# cpsw_9xuss_j7am0_CPSW_NUSS_VBUSP register map
Vendor: Texas Instruments
Registers are 32-bit, read-write, reset 0x0 unless marked. A register's access mark holds for its fields unless they carry their own. Offsets are as the file gives them; [hi:lo] are bit positions; {n}, {i} and the like mark numbered series; 'fields as' and 'values as' point back to an identical list.

## cpsw_9xuss_j7am0_CPSW_NUSS_VBUSP (part 3 of 3)
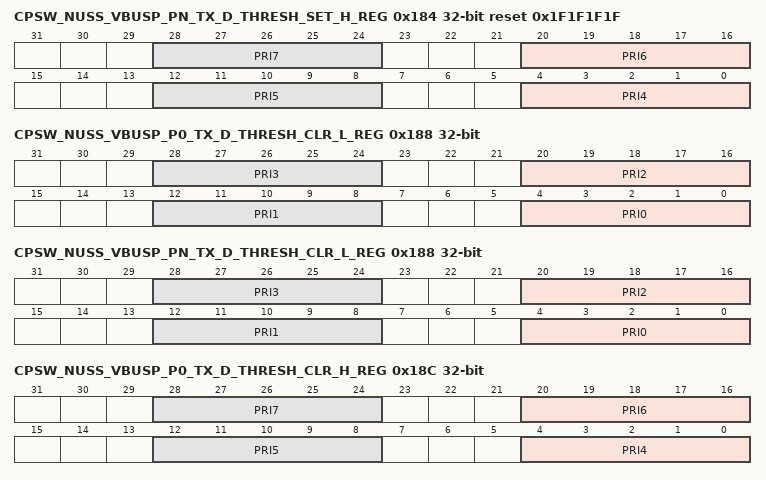
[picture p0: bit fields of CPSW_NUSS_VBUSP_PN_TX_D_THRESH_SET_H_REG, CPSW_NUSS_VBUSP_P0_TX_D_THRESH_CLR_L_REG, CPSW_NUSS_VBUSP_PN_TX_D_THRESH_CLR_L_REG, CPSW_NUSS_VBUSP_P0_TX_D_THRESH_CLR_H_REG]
0x184 CPSW_NUSS_VBUSP_PN_TX_D_THRESH_SET_H_REG reset 0x1F1F1F1F
  [8n-28:8n-32] PRI{n} (n=4..7) — Port Priority Based Flow Control Threshold Set Value for Priority {n}
0x184 CPSW_NUSS_VBUSP_PN_TX_D_THRESH_SET_H_REG reset 0x1F1F1F1F
  fields as CPSW_NUSS_VBUSP_PN_TX_D_THRESH_SET_H_REG
0x184 CPSW_NUSS_VBUSP_PN_TX_D_THRESH_SET_H_REG reset 0x1F1F1F1F
  fields as CPSW_NUSS_VBUSP_PN_TX_D_THRESH_SET_H_REG
0x184 CPSW_NUSS_VBUSP_PN_TX_D_THRESH_SET_H_REG reset 0x1F1F1F1F
  fields as CPSW_NUSS_VBUSP_PN_TX_D_THRESH_SET_H_REG
0x184 CPSW_NUSS_VBUSP_PN_TX_D_THRESH_SET_H_REG reset 0x1F1F1F1F
  fields as CPSW_NUSS_VBUSP_PN_TX_D_THRESH_SET_H_REG
0x184 CPSW_NUSS_VBUSP_PN_TX_D_THRESH_SET_H_REG reset 0x1F1F1F1F
  fields as CPSW_NUSS_VBUSP_PN_TX_D_THRESH_SET_H_REG
0x184 CPSW_NUSS_VBUSP_PN_TX_D_THRESH_SET_H_REG reset 0x1F1F1F1F
  fields as CPSW_NUSS_VBUSP_PN_TX_D_THRESH_SET_H_REG
0x184 CPSW_NUSS_VBUSP_PN_TX_D_THRESH_SET_H_REG reset 0x1F1F1F1F
  fields as CPSW_NUSS_VBUSP_PN_TX_D_THRESH_SET_H_REG
0x188 CPSW_NUSS_VBUSP_P0_TX_D_THRESH_CLR_L_REG
  [8n+4:8n] PRI{n} (n=0..3) — Port Priority Based Flow Control Threshold Clear Value for Priority {n}
0x188 CPSW_NUSS_VBUSP_PN_TX_D_THRESH_CLR_L_REG
  fields as CPSW_NUSS_VBUSP_P0_TX_D_THRESH_CLR_L_REG
0x188 CPSW_NUSS_VBUSP_PN_TX_D_THRESH_CLR_L_REG
  fields as CPSW_NUSS_VBUSP_P0_TX_D_THRESH_CLR_L_REG
0x188 CPSW_NUSS_VBUSP_PN_TX_D_THRESH_CLR_L_REG
  fields as CPSW_NUSS_VBUSP_P0_TX_D_THRESH_CLR_L_REG
0x188 CPSW_NUSS_VBUSP_PN_TX_D_THRESH_CLR_L_REG
  fields as CPSW_NUSS_VBUSP_P0_TX_D_THRESH_CLR_L_REG
0x188 CPSW_NUSS_VBUSP_PN_TX_D_THRESH_CLR_L_REG
  fields as CPSW_NUSS_VBUSP_P0_TX_D_THRESH_CLR_L_REG
0x188 CPSW_NUSS_VBUSP_PN_TX_D_THRESH_CLR_L_REG
  fields as CPSW_NUSS_VBUSP_P0_TX_D_THRESH_CLR_L_REG
0x188 CPSW_NUSS_VBUSP_PN_TX_D_THRESH_CLR_L_REG
  fields as CPSW_NUSS_VBUSP_P0_TX_D_THRESH_CLR_L_REG
0x188 CPSW_NUSS_VBUSP_PN_TX_D_THRESH_CLR_L_REG
  fields as CPSW_NUSS_VBUSP_P0_TX_D_THRESH_CLR_L_REG
0x18C CPSW_NUSS_VBUSP_P0_TX_D_THRESH_CLR_H_REG
  [8n-28:8n-32] PRI{n} (n=4..7) — Port Priority Based Flow Control Threshold Clear Value for Priority {n}
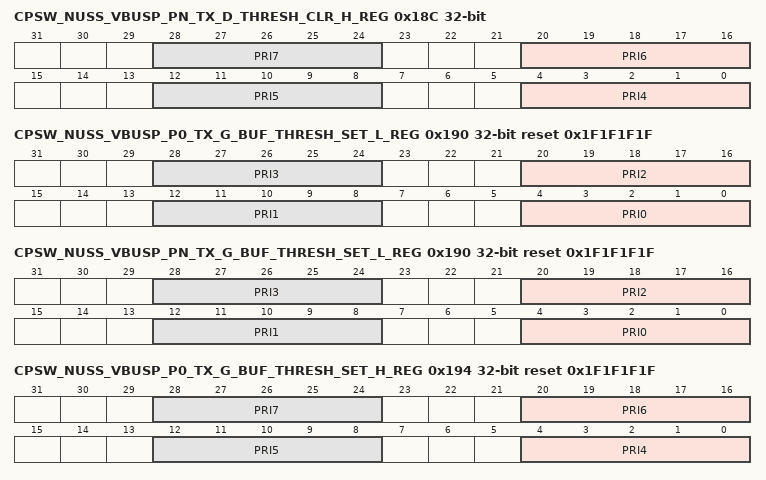
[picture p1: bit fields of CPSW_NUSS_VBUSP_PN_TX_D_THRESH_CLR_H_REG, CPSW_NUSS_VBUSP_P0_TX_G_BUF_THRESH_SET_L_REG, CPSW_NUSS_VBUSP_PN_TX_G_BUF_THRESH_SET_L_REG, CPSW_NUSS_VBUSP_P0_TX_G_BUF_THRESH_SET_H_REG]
0x18C CPSW_NUSS_VBUSP_PN_TX_D_THRESH_CLR_H_REG
  fields as CPSW_NUSS_VBUSP_P0_TX_D_THRESH_CLR_H_REG
0x18C CPSW_NUSS_VBUSP_PN_TX_D_THRESH_CLR_H_REG
  fields as CPSW_NUSS_VBUSP_P0_TX_D_THRESH_CLR_H_REG
0x18C CPSW_NUSS_VBUSP_PN_TX_D_THRESH_CLR_H_REG
  fields as CPSW_NUSS_VBUSP_P0_TX_D_THRESH_CLR_H_REG
0x18C CPSW_NUSS_VBUSP_PN_TX_D_THRESH_CLR_H_REG
  fields as CPSW_NUSS_VBUSP_P0_TX_D_THRESH_CLR_H_REG
0x18C CPSW_NUSS_VBUSP_PN_TX_D_THRESH_CLR_H_REG
  fields as CPSW_NUSS_VBUSP_P0_TX_D_THRESH_CLR_H_REG
0x18C CPSW_NUSS_VBUSP_PN_TX_D_THRESH_CLR_H_REG
  fields as CPSW_NUSS_VBUSP_P0_TX_D_THRESH_CLR_H_REG
0x18C CPSW_NUSS_VBUSP_PN_TX_D_THRESH_CLR_H_REG
  fields as CPSW_NUSS_VBUSP_P0_TX_D_THRESH_CLR_H_REG
0x18C CPSW_NUSS_VBUSP_PN_TX_D_THRESH_CLR_H_REG
  fields as CPSW_NUSS_VBUSP_P0_TX_D_THRESH_CLR_H_REG
0x190 CPSW_NUSS_VBUSP_P0_TX_G_BUF_THRESH_SET_L_REG reset 0x1F1F1F1F
  [8n+4:8n] PRI{n} (n=0..3) — Port Priority Based Flow Control Threshold Set Value for Priority {n}
0x190 CPSW_NUSS_VBUSP_PN_TX_G_BUF_THRESH_SET_L_REG reset 0x1F1F1F1F
  fields as CPSW_NUSS_VBUSP_P0_TX_G_BUF_THRESH_SET_L_REG
0x190 CPSW_NUSS_VBUSP_PN_TX_G_BUF_THRESH_SET_L_REG reset 0x1F1F1F1F
  fields as CPSW_NUSS_VBUSP_P0_TX_G_BUF_THRESH_SET_L_REG
0x190 CPSW_NUSS_VBUSP_PN_TX_G_BUF_THRESH_SET_L_REG reset 0x1F1F1F1F
  fields as CPSW_NUSS_VBUSP_P0_TX_G_BUF_THRESH_SET_L_REG
0x190 CPSW_NUSS_VBUSP_PN_TX_G_BUF_THRESH_SET_L_REG reset 0x1F1F1F1F
  fields as CPSW_NUSS_VBUSP_P0_TX_G_BUF_THRESH_SET_L_REG
0x190 CPSW_NUSS_VBUSP_PN_TX_G_BUF_THRESH_SET_L_REG reset 0x1F1F1F1F
  fields as CPSW_NUSS_VBUSP_P0_TX_G_BUF_THRESH_SET_L_REG
0x190 CPSW_NUSS_VBUSP_PN_TX_G_BUF_THRESH_SET_L_REG reset 0x1F1F1F1F
  fields as CPSW_NUSS_VBUSP_P0_TX_G_BUF_THRESH_SET_L_REG
0x190 CPSW_NUSS_VBUSP_PN_TX_G_BUF_THRESH_SET_L_REG reset 0x1F1F1F1F
  fields as CPSW_NUSS_VBUSP_P0_TX_G_BUF_THRESH_SET_L_REG
0x190 CPSW_NUSS_VBUSP_PN_TX_G_BUF_THRESH_SET_L_REG reset 0x1F1F1F1F
  fields as CPSW_NUSS_VBUSP_P0_TX_G_BUF_THRESH_SET_L_REG
0x194 CPSW_NUSS_VBUSP_P0_TX_G_BUF_THRESH_SET_H_REG reset 0x1F1F1F1F
  fields as CPSW_NUSS_VBUSP_PN_TX_D_THRESH_SET_H_REG
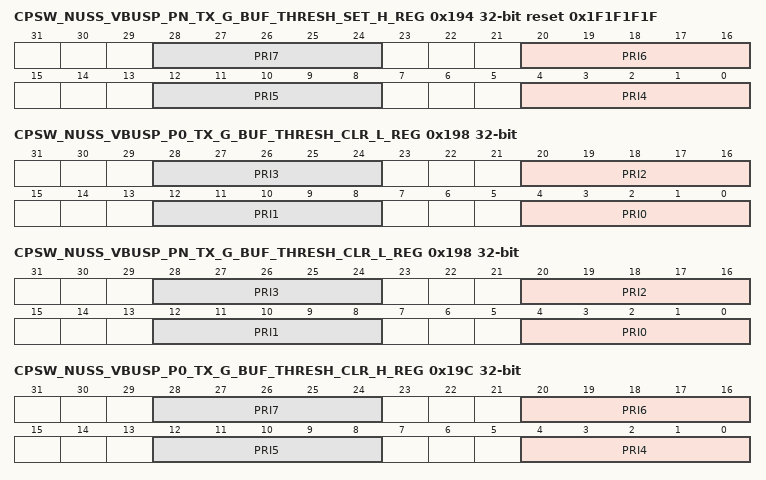
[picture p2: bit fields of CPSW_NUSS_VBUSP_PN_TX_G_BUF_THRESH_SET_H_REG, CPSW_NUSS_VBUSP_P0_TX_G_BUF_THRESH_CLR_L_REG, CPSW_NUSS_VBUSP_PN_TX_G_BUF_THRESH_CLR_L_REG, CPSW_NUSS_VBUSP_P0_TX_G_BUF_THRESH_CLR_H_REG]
0x194 CPSW_NUSS_VBUSP_PN_TX_G_BUF_THRESH_SET_H_REG reset 0x1F1F1F1F
  fields as CPSW_NUSS_VBUSP_PN_TX_D_THRESH_SET_H_REG
0x194 CPSW_NUSS_VBUSP_PN_TX_G_BUF_THRESH_SET_H_REG reset 0x1F1F1F1F
  fields as CPSW_NUSS_VBUSP_PN_TX_D_THRESH_SET_H_REG
0x194 CPSW_NUSS_VBUSP_PN_TX_G_BUF_THRESH_SET_H_REG reset 0x1F1F1F1F
  fields as CPSW_NUSS_VBUSP_PN_TX_D_THRESH_SET_H_REG
0x194 CPSW_NUSS_VBUSP_PN_TX_G_BUF_THRESH_SET_H_REG reset 0x1F1F1F1F
  fields as CPSW_NUSS_VBUSP_PN_TX_D_THRESH_SET_H_REG
0x194 CPSW_NUSS_VBUSP_PN_TX_G_BUF_THRESH_SET_H_REG reset 0x1F1F1F1F
  fields as CPSW_NUSS_VBUSP_PN_TX_D_THRESH_SET_H_REG
0x194 CPSW_NUSS_VBUSP_PN_TX_G_BUF_THRESH_SET_H_REG reset 0x1F1F1F1F
  fields as CPSW_NUSS_VBUSP_PN_TX_D_THRESH_SET_H_REG
0x194 CPSW_NUSS_VBUSP_PN_TX_G_BUF_THRESH_SET_H_REG reset 0x1F1F1F1F
  fields as CPSW_NUSS_VBUSP_PN_TX_D_THRESH_SET_H_REG
0x194 CPSW_NUSS_VBUSP_PN_TX_G_BUF_THRESH_SET_H_REG reset 0x1F1F1F1F
  fields as CPSW_NUSS_VBUSP_PN_TX_D_THRESH_SET_H_REG
0x198 CPSW_NUSS_VBUSP_P0_TX_G_BUF_THRESH_CLR_L_REG
  fields as CPSW_NUSS_VBUSP_P0_TX_D_THRESH_CLR_L_REG
0x198 CPSW_NUSS_VBUSP_PN_TX_G_BUF_THRESH_CLR_L_REG
  fields as CPSW_NUSS_VBUSP_P0_TX_D_THRESH_CLR_L_REG
0x198 CPSW_NUSS_VBUSP_PN_TX_G_BUF_THRESH_CLR_L_REG
  fields as CPSW_NUSS_VBUSP_P0_TX_D_THRESH_CLR_L_REG
0x198 CPSW_NUSS_VBUSP_PN_TX_G_BUF_THRESH_CLR_L_REG
  fields as CPSW_NUSS_VBUSP_P0_TX_D_THRESH_CLR_L_REG
0x198 CPSW_NUSS_VBUSP_PN_TX_G_BUF_THRESH_CLR_L_REG
  fields as CPSW_NUSS_VBUSP_P0_TX_D_THRESH_CLR_L_REG
0x198 CPSW_NUSS_VBUSP_PN_TX_G_BUF_THRESH_CLR_L_REG
  fields as CPSW_NUSS_VBUSP_P0_TX_D_THRESH_CLR_L_REG
0x198 CPSW_NUSS_VBUSP_PN_TX_G_BUF_THRESH_CLR_L_REG
  fields as CPSW_NUSS_VBUSP_P0_TX_D_THRESH_CLR_L_REG
0x198 CPSW_NUSS_VBUSP_PN_TX_G_BUF_THRESH_CLR_L_REG
  fields as CPSW_NUSS_VBUSP_P0_TX_D_THRESH_CLR_L_REG
0x198 CPSW_NUSS_VBUSP_PN_TX_G_BUF_THRESH_CLR_L_REG
  fields as CPSW_NUSS_VBUSP_P0_TX_D_THRESH_CLR_L_REG
0x19C CPSW_NUSS_VBUSP_P0_TX_G_BUF_THRESH_CLR_H_REG
  fields as CPSW_NUSS_VBUSP_P0_TX_D_THRESH_CLR_H_REG
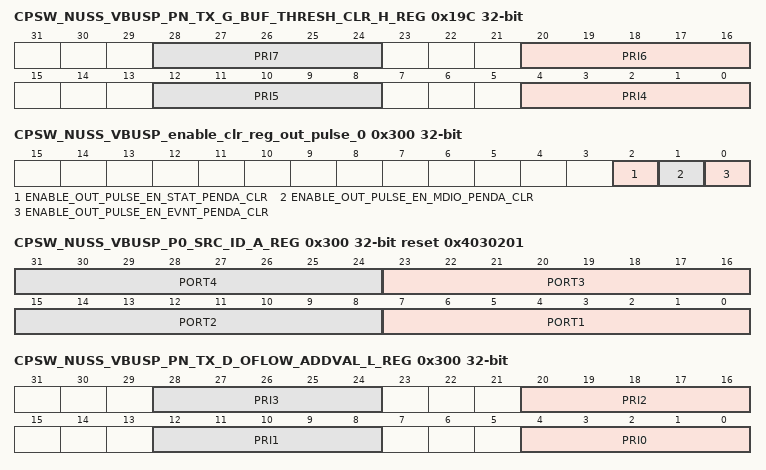
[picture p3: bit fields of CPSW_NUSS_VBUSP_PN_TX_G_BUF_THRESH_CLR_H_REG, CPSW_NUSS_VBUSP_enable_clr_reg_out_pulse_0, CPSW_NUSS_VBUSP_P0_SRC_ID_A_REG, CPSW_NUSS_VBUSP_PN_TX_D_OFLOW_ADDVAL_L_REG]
0x19C CPSW_NUSS_VBUSP_PN_TX_G_BUF_THRESH_CLR_H_REG
  fields as CPSW_NUSS_VBUSP_P0_TX_D_THRESH_CLR_H_REG
0x19C CPSW_NUSS_VBUSP_PN_TX_G_BUF_THRESH_CLR_H_REG
  fields as CPSW_NUSS_VBUSP_P0_TX_D_THRESH_CLR_H_REG
0x19C CPSW_NUSS_VBUSP_PN_TX_G_BUF_THRESH_CLR_H_REG
  fields as CPSW_NUSS_VBUSP_P0_TX_D_THRESH_CLR_H_REG
0x19C CPSW_NUSS_VBUSP_PN_TX_G_BUF_THRESH_CLR_H_REG
  fields as CPSW_NUSS_VBUSP_P0_TX_D_THRESH_CLR_H_REG
0x19C CPSW_NUSS_VBUSP_PN_TX_G_BUF_THRESH_CLR_H_REG
  fields as CPSW_NUSS_VBUSP_P0_TX_D_THRESH_CLR_H_REG
0x19C CPSW_NUSS_VBUSP_PN_TX_G_BUF_THRESH_CLR_H_REG
  fields as CPSW_NUSS_VBUSP_P0_TX_D_THRESH_CLR_H_REG
0x19C CPSW_NUSS_VBUSP_PN_TX_G_BUF_THRESH_CLR_H_REG
  fields as CPSW_NUSS_VBUSP_P0_TX_D_THRESH_CLR_H_REG
0x19C CPSW_NUSS_VBUSP_PN_TX_G_BUF_THRESH_CLR_H_REG
  fields as CPSW_NUSS_VBUSP_P0_TX_D_THRESH_CLR_H_REG
0x1A0 CPSW_NUSS_VBUSP_ENET_PN_TX_PRI_BCNT_REG
  [31:0] PN_TX_PRIN_BCNT — ENET Port n PRIORITY N Packet Byte Count
0x1C0 CPSW_NUSS_VBUSP_ENET_PN_TX_PRI_DROP_REG
  [31:0] PN_TX_PRIN_DROP — ENET Port n PRIORITY N Packet Drop Count
0x1E0 CPSW_NUSS_VBUSP_ENET_PN_TX_PRI_DROP_BCNT_REG
  [31:0] PN_TX_PRIN_DROP_BCNT — ENET Port n PRIORITY N Packet Drop Byte Count
0x300 CPSW_NUSS_VBUSP_enable_clr_reg_out_pulse_0 access not given
  [2] ENABLE_OUT_PULSE_EN_STAT_PENDA_CLR — Enable Clear for out_pulse_en_stat_penda (access R/W1TC)
  [1] ENABLE_OUT_PULSE_EN_MDIO_PENDA_CLR — Enable Clear for out_pulse_en_mdio_penda (access R/W1TC)
  [0] ENABLE_OUT_PULSE_EN_EVNT_PENDA_CLR — Enable Clear for out_pulse_en_evnt_penda (access R/W1TC)
0x300 CPSW_NUSS_VBUSP_P0_SRC_ID_A_REG reset 0x4030201
  [8n-1:8n-8] PORT{n} (n=1..4) — Port {n} CPPI Info Word0 Source ID Value
0x300 CPSW_NUSS_VBUSP_PN_TX_D_OFLOW_ADDVAL_L_REG
  [8n+4:8n] PRI{n} (n=0..3) — Port PFC Destination Based Out Flow Add Value for Priority {n}
0x300 CPSW_NUSS_VBUSP_PN_TX_D_OFLOW_ADDVAL_L_REG
  fields as CPSW_NUSS_VBUSP_PN_TX_D_OFLOW_ADDVAL_L_REG
0x300 CPSW_NUSS_VBUSP_PN_TX_D_OFLOW_ADDVAL_L_REG
  fields as CPSW_NUSS_VBUSP_PN_TX_D_OFLOW_ADDVAL_L_REG
0x300 CPSW_NUSS_VBUSP_PN_TX_D_OFLOW_ADDVAL_L_REG
  fields as CPSW_NUSS_VBUSP_PN_TX_D_OFLOW_ADDVAL_L_REG
0x300 CPSW_NUSS_VBUSP_PN_TX_D_OFLOW_ADDVAL_L_REG
  fields as CPSW_NUSS_VBUSP_PN_TX_D_OFLOW_ADDVAL_L_REG
0x300 CPSW_NUSS_VBUSP_PN_TX_D_OFLOW_ADDVAL_L_REG
  fields as CPSW_NUSS_VBUSP_PN_TX_D_OFLOW_ADDVAL_L_REG
0x300 CPSW_NUSS_VBUSP_PN_TX_D_OFLOW_ADDVAL_L_REG
  fields as CPSW_NUSS_VBUSP_PN_TX_D_OFLOW_ADDVAL_L_REG
0x300 CPSW_NUSS_VBUSP_PN_TX_D_OFLOW_ADDVAL_L_REG
  fields as CPSW_NUSS_VBUSP_PN_TX_D_OFLOW_ADDVAL_L_REG
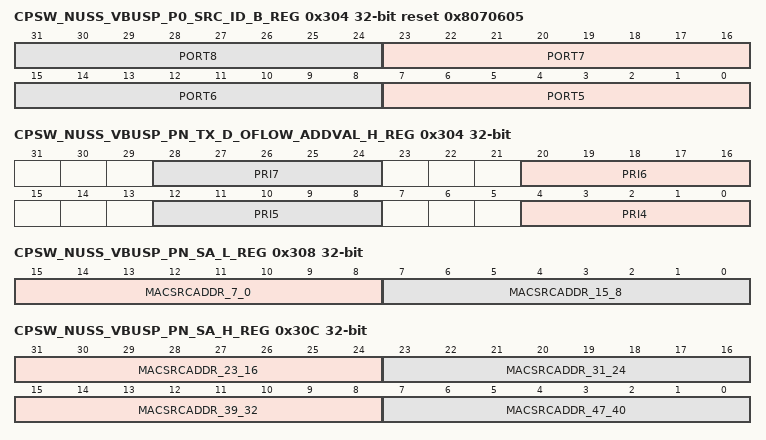
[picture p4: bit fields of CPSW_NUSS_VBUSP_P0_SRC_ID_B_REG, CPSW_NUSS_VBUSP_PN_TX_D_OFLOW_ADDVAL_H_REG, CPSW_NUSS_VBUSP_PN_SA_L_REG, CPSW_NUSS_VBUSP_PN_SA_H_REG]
0x304 CPSW_NUSS_VBUSP_P0_SRC_ID_B_REG reset 0x8070605
  [8n-33:8n-40] PORT{n} (n=5..8) — Port {n} CPPI Info Word0 Source ID Value
0x304 CPSW_NUSS_VBUSP_PN_TX_D_OFLOW_ADDVAL_H_REG
  [8n-28:8n-32] PRI{n} (n=4..7) — Port PFC Destination Based Out Flow Add Value for Priority {n}
0x304 CPSW_NUSS_VBUSP_PN_TX_D_OFLOW_ADDVAL_H_REG
  fields as CPSW_NUSS_VBUSP_PN_TX_D_OFLOW_ADDVAL_H_REG
0x304 CPSW_NUSS_VBUSP_PN_TX_D_OFLOW_ADDVAL_H_REG
  fields as CPSW_NUSS_VBUSP_PN_TX_D_OFLOW_ADDVAL_H_REG
0x304 CPSW_NUSS_VBUSP_PN_TX_D_OFLOW_ADDVAL_H_REG
  fields as CPSW_NUSS_VBUSP_PN_TX_D_OFLOW_ADDVAL_H_REG
0x304 CPSW_NUSS_VBUSP_PN_TX_D_OFLOW_ADDVAL_H_REG
  fields as CPSW_NUSS_VBUSP_PN_TX_D_OFLOW_ADDVAL_H_REG
0x304 CPSW_NUSS_VBUSP_PN_TX_D_OFLOW_ADDVAL_H_REG
  fields as CPSW_NUSS_VBUSP_PN_TX_D_OFLOW_ADDVAL_H_REG
0x304 CPSW_NUSS_VBUSP_PN_TX_D_OFLOW_ADDVAL_H_REG
  fields as CPSW_NUSS_VBUSP_PN_TX_D_OFLOW_ADDVAL_H_REG
0x304 CPSW_NUSS_VBUSP_PN_TX_D_OFLOW_ADDVAL_H_REG
  fields as CPSW_NUSS_VBUSP_PN_TX_D_OFLOW_ADDVAL_H_REG
0x308 CPSW_NUSS_VBUSP_PN_SA_L_REG
  [15:8] MACSRCADDR_7_0 — Source Address Lower 8 bits
  [7:0] MACSRCADDR_15_8 — Source Address bits 15:8
0x308 CPSW_NUSS_VBUSP_PN_SA_L_REG
  fields as CPSW_NUSS_VBUSP_PN_SA_L_REG
0x308 CPSW_NUSS_VBUSP_PN_SA_L_REG
  fields as CPSW_NUSS_VBUSP_PN_SA_L_REG
0x308 CPSW_NUSS_VBUSP_PN_SA_L_REG
  fields as CPSW_NUSS_VBUSP_PN_SA_L_REG
0x308 CPSW_NUSS_VBUSP_PN_SA_L_REG
  fields as CPSW_NUSS_VBUSP_PN_SA_L_REG
0x308 CPSW_NUSS_VBUSP_PN_SA_L_REG
  fields as CPSW_NUSS_VBUSP_PN_SA_L_REG
0x308 CPSW_NUSS_VBUSP_PN_SA_L_REG
  fields as CPSW_NUSS_VBUSP_PN_SA_L_REG
0x308 CPSW_NUSS_VBUSP_PN_SA_L_REG
  fields as CPSW_NUSS_VBUSP_PN_SA_L_REG
0x30C CPSW_NUSS_VBUSP_PN_SA_H_REG
  [31:24] MACSRCADDR_23_16 — Source Address bits 23:16
  [23:16] MACSRCADDR_31_24 — Source Address bits 31:24
  [15:8] MACSRCADDR_39_32 — Source Address bits 39:32
  [7:0] MACSRCADDR_47_40 — Source Address bits 47:40
0x30C CPSW_NUSS_VBUSP_PN_SA_H_REG
  fields as CPSW_NUSS_VBUSP_PN_SA_H_REG
0x30C CPSW_NUSS_VBUSP_PN_SA_H_REG
  fields as CPSW_NUSS_VBUSP_PN_SA_H_REG
0x30C CPSW_NUSS_VBUSP_PN_SA_H_REG
  fields as CPSW_NUSS_VBUSP_PN_SA_H_REG
0x30C CPSW_NUSS_VBUSP_PN_SA_H_REG
  fields as CPSW_NUSS_VBUSP_PN_SA_H_REG
0x30C CPSW_NUSS_VBUSP_PN_SA_H_REG
  fields as CPSW_NUSS_VBUSP_PN_SA_H_REG
0x30C CPSW_NUSS_VBUSP_PN_SA_H_REG
  fields as CPSW_NUSS_VBUSP_PN_SA_H_REG
0x30C CPSW_NUSS_VBUSP_PN_SA_H_REG
  fields as CPSW_NUSS_VBUSP_PN_SA_H_REG
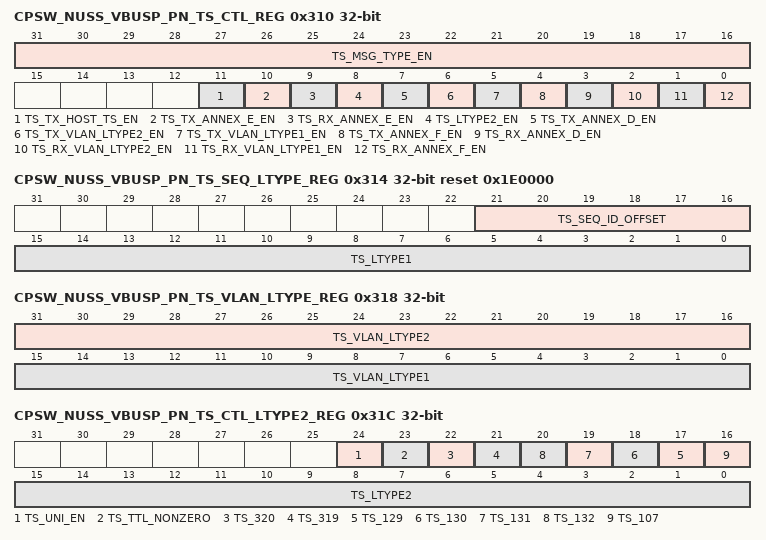
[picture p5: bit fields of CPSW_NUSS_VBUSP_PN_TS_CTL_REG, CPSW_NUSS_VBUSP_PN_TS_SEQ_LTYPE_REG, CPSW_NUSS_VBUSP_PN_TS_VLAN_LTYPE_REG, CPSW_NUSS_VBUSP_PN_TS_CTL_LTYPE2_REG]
0x310 CPSW_NUSS_VBUSP_PN_TS_CTL_REG
  [31:16] TS_MSG_TYPE_EN — Time Sync Message Type Enable
  [11] TS_TX_HOST_TS_EN — Time Sync Transmit Host Time Stamp Enable
  [10] TS_TX_ANNEX_E_EN — Time Synce Transmit Annex E Enable
  [9] TS_RX_ANNEX_E_EN — Time Synce Receive Annex E Enable
  [8] TS_LTYPE2_EN — Time Sync LTYPE 2 enable transmit and receive
  [7] TS_TX_ANNEX_D_EN — Time Synce Transmit Annex D Enable
  [6] TS_TX_VLAN_LTYPE2_EN — Time Sync Transmit VLAN LTYPE 2 enable
  [5] TS_TX_VLAN_LTYPE1_EN — Time Sync Transmit VLAN LTYPE 1 enable
  [4] TS_TX_ANNEX_F_EN — Time Synce Transmit Annex F Enable
  [3] TS_RX_ANNEX_D_EN — Time Synce Receive Annex D Enable
  [2] TS_RX_VLAN_LTYPE2_EN — Time Sync Receive VLAN LTYPE 2 enable
  [1] TS_RX_VLAN_LTYPE1_EN — Time Sync Receive VLAN LTYPE 1 enable
  [0] TS_RX_ANNEX_F_EN — Time Synce Receive Annex F Enable
0x310 CPSW_NUSS_VBUSP_PN_TS_CTL_REG
  fields as CPSW_NUSS_VBUSP_PN_TS_CTL_REG
0x310 CPSW_NUSS_VBUSP_PN_TS_CTL_REG
  fields as CPSW_NUSS_VBUSP_PN_TS_CTL_REG
0x310 CPSW_NUSS_VBUSP_PN_TS_CTL_REG
  fields as CPSW_NUSS_VBUSP_PN_TS_CTL_REG
0x310 CPSW_NUSS_VBUSP_PN_TS_CTL_REG
  fields as CPSW_NUSS_VBUSP_PN_TS_CTL_REG
0x310 CPSW_NUSS_VBUSP_PN_TS_CTL_REG
  fields as CPSW_NUSS_VBUSP_PN_TS_CTL_REG
0x310 CPSW_NUSS_VBUSP_PN_TS_CTL_REG
  fields as CPSW_NUSS_VBUSP_PN_TS_CTL_REG
0x310 CPSW_NUSS_VBUSP_PN_TS_CTL_REG
  fields as CPSW_NUSS_VBUSP_PN_TS_CTL_REG
0x314 CPSW_NUSS_VBUSP_PN_TS_SEQ_LTYPE_REG reset 0x1E0000
  [21:16] TS_SEQ_ID_OFFSET — Time Sync Sequence ID Offset
  [15:0] TS_LTYPE1 — Time Sync LTYPE1
0x314 CPSW_NUSS_VBUSP_PN_TS_SEQ_LTYPE_REG reset 0x1E0000
  fields as CPSW_NUSS_VBUSP_PN_TS_SEQ_LTYPE_REG
0x314 CPSW_NUSS_VBUSP_PN_TS_SEQ_LTYPE_REG reset 0x1E0000
  fields as CPSW_NUSS_VBUSP_PN_TS_SEQ_LTYPE_REG
0x314 CPSW_NUSS_VBUSP_PN_TS_SEQ_LTYPE_REG reset 0x1E0000
  fields as CPSW_NUSS_VBUSP_PN_TS_SEQ_LTYPE_REG
0x314 CPSW_NUSS_VBUSP_PN_TS_SEQ_LTYPE_REG reset 0x1E0000
  fields as CPSW_NUSS_VBUSP_PN_TS_SEQ_LTYPE_REG
0x314 CPSW_NUSS_VBUSP_PN_TS_SEQ_LTYPE_REG reset 0x1E0000
  fields as CPSW_NUSS_VBUSP_PN_TS_SEQ_LTYPE_REG
0x314 CPSW_NUSS_VBUSP_PN_TS_SEQ_LTYPE_REG reset 0x1E0000
  fields as CPSW_NUSS_VBUSP_PN_TS_SEQ_LTYPE_REG
0x314 CPSW_NUSS_VBUSP_PN_TS_SEQ_LTYPE_REG reset 0x1E0000
  fields as CPSW_NUSS_VBUSP_PN_TS_SEQ_LTYPE_REG
0x318 CPSW_NUSS_VBUSP_PN_TS_VLAN_LTYPE_REG
  [31:16] TS_VLAN_LTYPE2 — Time Sync VLAN LTYPE2
  [15:0] TS_VLAN_LTYPE1 — Time Sync VLAN LTYPE1
0x318 CPSW_NUSS_VBUSP_PN_TS_VLAN_LTYPE_REG
  fields as CPSW_NUSS_VBUSP_PN_TS_VLAN_LTYPE_REG
0x318 CPSW_NUSS_VBUSP_PN_TS_VLAN_LTYPE_REG
  fields as CPSW_NUSS_VBUSP_PN_TS_VLAN_LTYPE_REG
0x318 CPSW_NUSS_VBUSP_PN_TS_VLAN_LTYPE_REG
  fields as CPSW_NUSS_VBUSP_PN_TS_VLAN_LTYPE_REG
0x318 CPSW_NUSS_VBUSP_PN_TS_VLAN_LTYPE_REG
  fields as CPSW_NUSS_VBUSP_PN_TS_VLAN_LTYPE_REG
0x318 CPSW_NUSS_VBUSP_PN_TS_VLAN_LTYPE_REG
  fields as CPSW_NUSS_VBUSP_PN_TS_VLAN_LTYPE_REG
0x318 CPSW_NUSS_VBUSP_PN_TS_VLAN_LTYPE_REG
  fields as CPSW_NUSS_VBUSP_PN_TS_VLAN_LTYPE_REG
0x318 CPSW_NUSS_VBUSP_PN_TS_VLAN_LTYPE_REG
  fields as CPSW_NUSS_VBUSP_PN_TS_VLAN_LTYPE_REG
0x31C CPSW_NUSS_VBUSP_PN_TS_CTL_LTYPE2_REG
  [24] TS_UNI_EN — Time Sync Unicast Enable
  [23] TS_TTL_NONZERO — Time Sync Time to Live Non-zero Enable
  [22] TS_320 — Time Sync Destination IP Address 320 Enable
  [21] TS_319 — Time Sync Destination IP Address 319 Enable
  [n-112] TS_{n} (n=129..132) — Time Sync Destination IP Address {n} Enable
  [16] TS_107 — Time Sync Destination IP Address 107 Enable
  [15:0] TS_LTYPE2 — Time Sync LTYPE2
0x31C CPSW_NUSS_VBUSP_PN_TS_CTL_LTYPE2_REG
  fields as CPSW_NUSS_VBUSP_PN_TS_CTL_LTYPE2_REG
0x31C CPSW_NUSS_VBUSP_PN_TS_CTL_LTYPE2_REG
  fields as CPSW_NUSS_VBUSP_PN_TS_CTL_LTYPE2_REG
0x31C CPSW_NUSS_VBUSP_PN_TS_CTL_LTYPE2_REG
  fields as CPSW_NUSS_VBUSP_PN_TS_CTL_LTYPE2_REG
0x31C CPSW_NUSS_VBUSP_PN_TS_CTL_LTYPE2_REG
  fields as CPSW_NUSS_VBUSP_PN_TS_CTL_LTYPE2_REG
0x31C CPSW_NUSS_VBUSP_PN_TS_CTL_LTYPE2_REG
  fields as CPSW_NUSS_VBUSP_PN_TS_CTL_LTYPE2_REG
0x31C CPSW_NUSS_VBUSP_PN_TS_CTL_LTYPE2_REG
  fields as CPSW_NUSS_VBUSP_PN_TS_CTL_LTYPE2_REG
0x31C CPSW_NUSS_VBUSP_PN_TS_CTL_LTYPE2_REG
  fields as CPSW_NUSS_VBUSP_PN_TS_CTL_LTYPE2_REG
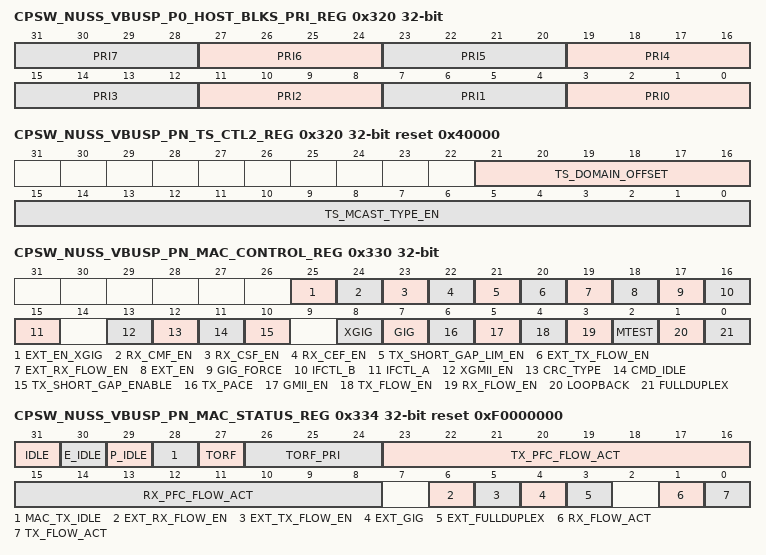
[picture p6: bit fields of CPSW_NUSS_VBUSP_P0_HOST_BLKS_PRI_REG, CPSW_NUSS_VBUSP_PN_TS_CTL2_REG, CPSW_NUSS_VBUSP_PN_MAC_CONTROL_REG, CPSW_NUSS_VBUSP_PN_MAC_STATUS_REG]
0x320 CPSW_NUSS_VBUSP_P0_HOST_BLKS_PRI_REG
  [4n+3:4n] PRI{n} (n=0..7) — Priority {n} Host Blocks
0x320 CPSW_NUSS_VBUSP_PN_TS_CTL2_REG reset 0x40000
  [21:16] TS_DOMAIN_OFFSET — Time Sync Domain Offset
  [15:0] TS_MCAST_TYPE_EN — Time Sync Multicast Destination Address Type Enable
0x320 CPSW_NUSS_VBUSP_PN_TS_CTL2_REG reset 0x40000
  fields as CPSW_NUSS_VBUSP_PN_TS_CTL2_REG
0x320 CPSW_NUSS_VBUSP_PN_TS_CTL2_REG reset 0x40000
  fields as CPSW_NUSS_VBUSP_PN_TS_CTL2_REG
0x320 CPSW_NUSS_VBUSP_PN_TS_CTL2_REG reset 0x40000
  fields as CPSW_NUSS_VBUSP_PN_TS_CTL2_REG
0x320 CPSW_NUSS_VBUSP_PN_TS_CTL2_REG reset 0x40000
  fields as CPSW_NUSS_VBUSP_PN_TS_CTL2_REG
0x320 CPSW_NUSS_VBUSP_PN_TS_CTL2_REG reset 0x40000
  fields as CPSW_NUSS_VBUSP_PN_TS_CTL2_REG
0x320 CPSW_NUSS_VBUSP_PN_TS_CTL2_REG reset 0x40000
  fields as CPSW_NUSS_VBUSP_PN_TS_CTL2_REG
0x320 CPSW_NUSS_VBUSP_PN_TS_CTL2_REG reset 0x40000
  fields as CPSW_NUSS_VBUSP_PN_TS_CTL2_REG
0x330 CPSW_NUSS_VBUSP_PN_MAC_CONTROL_REG
  [25] EXT_EN_XGIG — 10G External Enable
  [24] RX_CMF_EN — RX Copy MAC Control Frames Enable
  [23] RX_CSF_EN — RX Copy Short Frames Enable
  [22] RX_CEF_EN — RX Copy Error Frames Enable
  [21] TX_SHORT_GAP_LIM_EN — Transmit Short Gap Limit Enable
  [20] EXT_TX_FLOW_EN — External Transmit Flow Control Enable
  [19] EXT_RX_FLOW_EN — External Receive Flow Control Enable
  [18] EXT_EN — External Enable
  [17] GIG_FORCE — Gigabit Mode Force
  [16] IFCTL_B — Interface Control B
  [15] IFCTL_A — Interface Control A
  [13] XGMII_EN — XGMII Enable
  [12] CRC_TYPE — Port CRC Type
  [11] CMD_IDLE — Command Idle
  [10] TX_SHORT_GAP_ENABLE — Transmit Short Gap Enable
  [8] XGIG — 10 Gigabit Mode
  [7] GIG — Gigabit Mode
  [6] TX_PACE — Transmit Pacing Enable
  [5] GMII_EN — GMII Enable
  [4] TX_FLOW_EN — Transmit Flow Control Enable
  [3] RX_FLOW_EN — Receive Flow Control Enable
  [2] MTEST — Manufacturing Test Mode
  [1] LOOPBACK — Loop Back Mode
  [0] FULLDUPLEX — Full Duplex mode
0x330 CPSW_NUSS_VBUSP_PN_MAC_CONTROL_REG
  fields as CPSW_NUSS_VBUSP_PN_MAC_CONTROL_REG
0x330 CPSW_NUSS_VBUSP_PN_MAC_CONTROL_REG
  [24] RX_CMF_EN — RX Copy MAC Control Frames Enable
  [23] RX_CSF_EN — RX Copy Short Frames Enable
  [22] RX_CEF_EN — RX Copy Error Frames Enable
  [21] TX_SHORT_GAP_LIM_EN — Transmit Short Gap Limit Enable
  [20] EXT_TX_FLOW_EN — External Transmit Flow Control Enable
  [19] EXT_RX_FLOW_EN — External Receive Flow Control Enable
  [18] EXT_EN — External Enable
  [17] GIG_FORCE — Gigabit Mode Force
  [16] IFCTL_B — Interface Control B
  [15] IFCTL_A — Interface Control A
  [12] CRC_TYPE — Port CRC Type
  [11] CMD_IDLE — Command Idle
  [10] TX_SHORT_GAP_ENABLE — Transmit Short Gap Enable
  [7] GIG — Gigabit Mode
  [6] TX_PACE — Transmit Pacing Enable
  [5] GMII_EN — GMII Enable
  [4] TX_FLOW_EN — Transmit Flow Control Enable
  [3] RX_FLOW_EN — Receive Flow Control Enable
  [2] MTEST — Manufacturing Test Mode
  [1] LOOPBACK — Loop Back Mode
  [0] FULLDUPLEX — Full Duplex mode
0x330 CPSW_NUSS_VBUSP_PN_MAC_CONTROL_REG
  [24] RX_CMF_EN — RX Copy MAC Control Frames Enable
  [23] RX_CSF_EN — RX Copy Short Frames Enable
  [22] RX_CEF_EN — RX Copy Error Frames Enable
  [21] TX_SHORT_GAP_LIM_EN — Transmit Short Gap Limit Enable
  [20] EXT_TX_FLOW_EN — External Transmit Flow Control Enable
  [19] EXT_RX_FLOW_EN — External Receive Flow Control Enable
  [18] EXT_EN — External Enable
  [17] GIG_FORCE — Gigabit Mode Force
  [16] IFCTL_B — Interface Control B
  [15] IFCTL_A — Interface Control A
  [12] CRC_TYPE — Port CRC Type
  [11] CMD_IDLE — Command Idle
  [10] TX_SHORT_GAP_ENABLE — Transmit Short Gap Enable
  [7] GIG — Gigabit Mode
  [6] TX_PACE — Transmit Pacing Enable
  [5] GMII_EN — GMII Enable
  [4] TX_FLOW_EN — Transmit Flow Control Enable
  [3] RX_FLOW_EN — Receive Flow Control Enable
  [2] MTEST — Manufacturing Test Mode
  [1] LOOPBACK — Loop Back Mode
  [0] FULLDUPLEX — Full Duplex mode
0x330 CPSW_NUSS_VBUSP_PN_MAC_CONTROL_REG
  [24] RX_CMF_EN — RX Copy MAC Control Frames Enable
  [23] RX_CSF_EN — RX Copy Short Frames Enable
  [22] RX_CEF_EN — RX Copy Error Frames Enable
  [21] TX_SHORT_GAP_LIM_EN — Transmit Short Gap Limit Enable
  [20] EXT_TX_FLOW_EN — External Transmit Flow Control Enable
  [19] EXT_RX_FLOW_EN — External Receive Flow Control Enable
  [18] EXT_EN — External Enable
  [17] GIG_FORCE — Gigabit Mode Force
  [16] IFCTL_B — Interface Control B
  [15] IFCTL_A — Interface Control A
  [12] CRC_TYPE — Port CRC Type
  [11] CMD_IDLE — Command Idle
  [10] TX_SHORT_GAP_ENABLE — Transmit Short Gap Enable
  [7] GIG — Gigabit Mode
  [6] TX_PACE — Transmit Pacing Enable
  [5] GMII_EN — GMII Enable
  [4] TX_FLOW_EN — Transmit Flow Control Enable
  [3] RX_FLOW_EN — Receive Flow Control Enable
  [2] MTEST — Manufacturing Test Mode
  [1] LOOPBACK — Loop Back Mode
  [0] FULLDUPLEX — Full Duplex mode
0x330 CPSW_NUSS_VBUSP_PN_MAC_CONTROL_REG
  [24] RX_CMF_EN — RX Copy MAC Control Frames Enable
  [23] RX_CSF_EN — RX Copy Short Frames Enable
  [22] RX_CEF_EN — RX Copy Error Frames Enable
  [21] TX_SHORT_GAP_LIM_EN — Transmit Short Gap Limit Enable
  [20] EXT_TX_FLOW_EN — External Transmit Flow Control Enable
  [19] EXT_RX_FLOW_EN — External Receive Flow Control Enable
  [18] EXT_EN — External Enable
  [17] GIG_FORCE — Gigabit Mode Force
  [16] IFCTL_B — Interface Control B
  [15] IFCTL_A — Interface Control A
  [12] CRC_TYPE — Port CRC Type
  [11] CMD_IDLE — Command Idle
  [10] TX_SHORT_GAP_ENABLE — Transmit Short Gap Enable
  [7] GIG — Gigabit Mode
  [6] TX_PACE — Transmit Pacing Enable
  [5] GMII_EN — GMII Enable
  [4] TX_FLOW_EN — Transmit Flow Control Enable
  [3] RX_FLOW_EN — Receive Flow Control Enable
  [2] MTEST — Manufacturing Test Mode
  [1] LOOPBACK — Loop Back Mode
  [0] FULLDUPLEX — Full Duplex mode
0x330 CPSW_NUSS_VBUSP_PN_MAC_CONTROL_REG
  [24] RX_CMF_EN — RX Copy MAC Control Frames Enable
  [23] RX_CSF_EN — RX Copy Short Frames Enable
  [22] RX_CEF_EN — RX Copy Error Frames Enable
  [21] TX_SHORT_GAP_LIM_EN — Transmit Short Gap Limit Enable
  [20] EXT_TX_FLOW_EN — External Transmit Flow Control Enable
  [19] EXT_RX_FLOW_EN — External Receive Flow Control Enable
  [18] EXT_EN — External Enable
  [17] GIG_FORCE — Gigabit Mode Force
  [16] IFCTL_B — Interface Control B
  [15] IFCTL_A — Interface Control A
  [12] CRC_TYPE — Port CRC Type
  [11] CMD_IDLE — Command Idle
  [10] TX_SHORT_GAP_ENABLE — Transmit Short Gap Enable
  [7] GIG — Gigabit Mode
  [6] TX_PACE — Transmit Pacing Enable
  [5] GMII_EN — GMII Enable
  [4] TX_FLOW_EN — Transmit Flow Control Enable
  [3] RX_FLOW_EN — Receive Flow Control Enable
  [2] MTEST — Manufacturing Test Mode
  [1] LOOPBACK — Loop Back Mode
  [0] FULLDUPLEX — Full Duplex mode
0x330 CPSW_NUSS_VBUSP_PN_MAC_CONTROL_REG
  [24] RX_CMF_EN — RX Copy MAC Control Frames Enable
  [23] RX_CSF_EN — RX Copy Short Frames Enable
  [22] RX_CEF_EN — RX Copy Error Frames Enable
  [21] TX_SHORT_GAP_LIM_EN — Transmit Short Gap Limit Enable
  [20] EXT_TX_FLOW_EN — External Transmit Flow Control Enable
  [19] EXT_RX_FLOW_EN — External Receive Flow Control Enable
  [18] EXT_EN — External Enable
  [17] GIG_FORCE — Gigabit Mode Force
  [16] IFCTL_B — Interface Control B
  [15] IFCTL_A — Interface Control A
  [12] CRC_TYPE — Port CRC Type
  [11] CMD_IDLE — Command Idle
  [10] TX_SHORT_GAP_ENABLE — Transmit Short Gap Enable
  [7] GIG — Gigabit Mode
  [6] TX_PACE — Transmit Pacing Enable
  [5] GMII_EN — GMII Enable
  [4] TX_FLOW_EN — Transmit Flow Control Enable
  [3] RX_FLOW_EN — Receive Flow Control Enable
  [2] MTEST — Manufacturing Test Mode
  [1] LOOPBACK — Loop Back Mode
  [0] FULLDUPLEX — Full Duplex mode
0x334 CPSW_NUSS_VBUSP_PN_MAC_STATUS_REG ro reset 0xF0000000
  [31] IDLE — cpxmac_sl IDLE
  [30] E_IDLE — Express cpxmac_sl IDLE
  [29] P_IDLE — Prempt cpxmac_sl IDLE
  [28] MAC_TX_IDLE — Prempt and Express cpxmac_sl Transmit IDLE
  [27] TORF — Top of receive FIFO flow control trigger occurred. This bit is write one to clear.
  [26:24] TORF_PRI — The lowest priority that caused top of receive FIFO flow control trigger since the last write to clear. This field is write 0x7 to clear.
  [23:16] TX_PFC_FLOW_ACT — Transmit Priority Based Flow Control Active (priority 7 down to 0)
  [15:8] RX_PFC_FLOW_ACT — Receive Priority Based Flow Control Active (priority 7 down to 0)
  [6] EXT_RX_FLOW_EN — External Transmit Flow Control Enable
  [5] EXT_TX_FLOW_EN — External Receive Flow Control Enable
  [4] EXT_GIG — External GIG mode
  [3] EXT_FULLDUPLEX — External Fullduplex
  [1] RX_FLOW_ACT — Receive Flow Control Active
  [0] TX_FLOW_ACT — Transmit Flow Control Active
0x334 CPSW_NUSS_VBUSP_PN_MAC_STATUS_REG ro reset 0xF0000000
  fields as CPSW_NUSS_VBUSP_PN_MAC_STATUS_REG
0x334 CPSW_NUSS_VBUSP_PN_MAC_STATUS_REG ro reset 0xF0000000
  fields as CPSW_NUSS_VBUSP_PN_MAC_STATUS_REG
0x334 CPSW_NUSS_VBUSP_PN_MAC_STATUS_REG ro reset 0xF0000000
  fields as CPSW_NUSS_VBUSP_PN_MAC_STATUS_REG
0x334 CPSW_NUSS_VBUSP_PN_MAC_STATUS_REG ro reset 0xF0000000
  fields as CPSW_NUSS_VBUSP_PN_MAC_STATUS_REG
0x334 CPSW_NUSS_VBUSP_PN_MAC_STATUS_REG ro reset 0xF0000000
  fields as CPSW_NUSS_VBUSP_PN_MAC_STATUS_REG
0x334 CPSW_NUSS_VBUSP_PN_MAC_STATUS_REG ro reset 0xF0000000
  fields as CPSW_NUSS_VBUSP_PN_MAC_STATUS_REG
0x334 CPSW_NUSS_VBUSP_PN_MAC_STATUS_REG ro reset 0xF0000000
  fields as CPSW_NUSS_VBUSP_PN_MAC_STATUS_REG
0x338 CPSW_NUSS_VBUSP_PN_MAC_SOFT_RESET_REG
  [0] SOFT_RESET — Software reset
0x338 CPSW_NUSS_VBUSP_PN_MAC_SOFT_RESET_REG
  [0] SOFT_RESET — Software reset
0x338 CPSW_NUSS_VBUSP_PN_MAC_SOFT_RESET_REG
  [0] SOFT_RESET — Software reset
0x338 CPSW_NUSS_VBUSP_PN_MAC_SOFT_RESET_REG
  [0] SOFT_RESET — Software reset
0x338 CPSW_NUSS_VBUSP_PN_MAC_SOFT_RESET_REG
  [0] SOFT_RESET — Software reset
0x338 CPSW_NUSS_VBUSP_PN_MAC_SOFT_RESET_REG
  [0] SOFT_RESET — Software reset
0x338 CPSW_NUSS_VBUSP_PN_MAC_SOFT_RESET_REG
  [0] SOFT_RESET — Software reset
0x338 CPSW_NUSS_VBUSP_PN_MAC_SOFT_RESET_REG
  [0] SOFT_RESET — Software reset
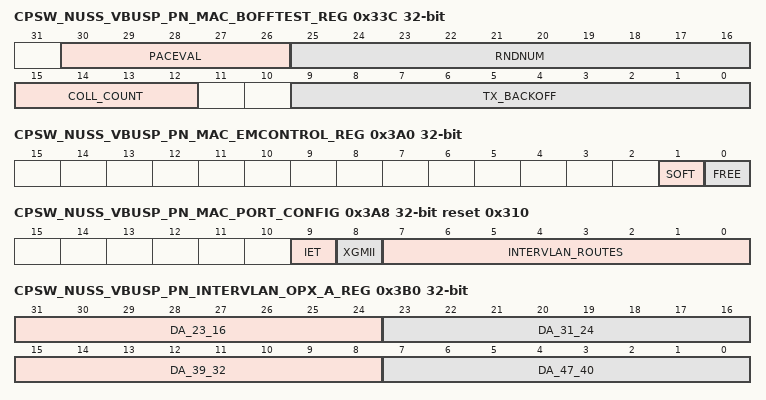
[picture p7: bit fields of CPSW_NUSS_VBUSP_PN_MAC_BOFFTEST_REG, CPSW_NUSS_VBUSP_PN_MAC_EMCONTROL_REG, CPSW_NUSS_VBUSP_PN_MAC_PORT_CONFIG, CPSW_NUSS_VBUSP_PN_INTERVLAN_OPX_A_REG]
0x33C CPSW_NUSS_VBUSP_PN_MAC_BOFFTEST_REG access per field
  [30:26] PACEVAL rw — Pacing Register Current Value
  [25:16] RNDNUM rw — Backoff Random Number Generator
  [15:12] COLL_COUNT ro — Collision Count
  [9:0] TX_BACKOFF ro — Backoff Count
0x33C CPSW_NUSS_VBUSP_PN_MAC_BOFFTEST_REG access per field
  fields as CPSW_NUSS_VBUSP_PN_MAC_BOFFTEST_REG
0x33C CPSW_NUSS_VBUSP_PN_MAC_BOFFTEST_REG access per field
  fields as CPSW_NUSS_VBUSP_PN_MAC_BOFFTEST_REG
0x33C CPSW_NUSS_VBUSP_PN_MAC_BOFFTEST_REG access per field
  fields as CPSW_NUSS_VBUSP_PN_MAC_BOFFTEST_REG
0x33C CPSW_NUSS_VBUSP_PN_MAC_BOFFTEST_REG access per field
  fields as CPSW_NUSS_VBUSP_PN_MAC_BOFFTEST_REG
0x33C CPSW_NUSS_VBUSP_PN_MAC_BOFFTEST_REG access per field
  fields as CPSW_NUSS_VBUSP_PN_MAC_BOFFTEST_REG
0x33C CPSW_NUSS_VBUSP_PN_MAC_BOFFTEST_REG access per field
  fields as CPSW_NUSS_VBUSP_PN_MAC_BOFFTEST_REG
0x33C CPSW_NUSS_VBUSP_PN_MAC_BOFFTEST_REG access per field
  fields as CPSW_NUSS_VBUSP_PN_MAC_BOFFTEST_REG
0x340 CPSW_NUSS_VBUSP_PN_MAC_RX_PAUSETIMER_REG
  [15:0] RX_PAUSETIMER — RX Pause Timer Value
0x340 CPSW_NUSS_VBUSP_PN_MAC_RX_PAUSETIMER_REG
  [15:0] RX_PAUSETIMER — RX Pause Timer Value
0x340 CPSW_NUSS_VBUSP_PN_MAC_RX_PAUSETIMER_REG
  [15:0] RX_PAUSETIMER — RX Pause Timer Value
0x340 CPSW_NUSS_VBUSP_PN_MAC_RX_PAUSETIMER_REG
  [15:0] RX_PAUSETIMER — RX Pause Timer Value
0x340 CPSW_NUSS_VBUSP_PN_MAC_RX_PAUSETIMER_REG
  [15:0] RX_PAUSETIMER — RX Pause Timer Value
0x340 CPSW_NUSS_VBUSP_PN_MAC_RX_PAUSETIMER_REG
  [15:0] RX_PAUSETIMER — RX Pause Timer Value
0x340 CPSW_NUSS_VBUSP_PN_MAC_RX_PAUSETIMER_REG
  [15:0] RX_PAUSETIMER — RX Pause Timer Value
0x340 CPSW_NUSS_VBUSP_PN_MAC_RX_PAUSETIMER_REG
  [15:0] RX_PAUSETIMER — RX Pause Timer Value
0x350 CPSW_NUSS_VBUSP_PN_MAC_RXN_PAUSETIMER_REG
  [15:0] RX_PAUSETIMER — RX Pause Timer Value
0x350 CPSW_NUSS_VBUSP_PN_MAC_RXN_PAUSETIMER_REG
  [15:0] RX_PAUSETIMER — RX Pause Timer Value
0x350 CPSW_NUSS_VBUSP_PN_MAC_RXN_PAUSETIMER_REG
  [15:0] RX_PAUSETIMER — RX Pause Timer Value
0x350 CPSW_NUSS_VBUSP_PN_MAC_RXN_PAUSETIMER_REG
  [15:0] RX_PAUSETIMER — RX Pause Timer Value
0x350 CPSW_NUSS_VBUSP_PN_MAC_RXN_PAUSETIMER_REG
  [15:0] RX_PAUSETIMER — RX Pause Timer Value
0x350 CPSW_NUSS_VBUSP_PN_MAC_RXN_PAUSETIMER_REG
  [15:0] RX_PAUSETIMER — RX Pause Timer Value
0x350 CPSW_NUSS_VBUSP_PN_MAC_RXN_PAUSETIMER_REG
  [15:0] RX_PAUSETIMER — RX Pause Timer Value
0x350 CPSW_NUSS_VBUSP_PN_MAC_RXN_PAUSETIMER_REG
  [15:0] RX_PAUSETIMER — RX Pause Timer Value
0x370 CPSW_NUSS_VBUSP_PN_MAC_TX_PAUSETIMER_REG
  [15:0] TX_PAUSETIMER — TX Pause Timer Value
0x370 CPSW_NUSS_VBUSP_PN_MAC_TX_PAUSETIMER_REG
  [15:0] TX_PAUSETIMER — TX Pause Timer Value
0x370 CPSW_NUSS_VBUSP_PN_MAC_TX_PAUSETIMER_REG
  [15:0] TX_PAUSETIMER — TX Pause Timer Value
0x370 CPSW_NUSS_VBUSP_PN_MAC_TX_PAUSETIMER_REG
  [15:0] TX_PAUSETIMER — TX Pause Timer Value
0x370 CPSW_NUSS_VBUSP_PN_MAC_TX_PAUSETIMER_REG
  [15:0] TX_PAUSETIMER — TX Pause Timer Value
0x370 CPSW_NUSS_VBUSP_PN_MAC_TX_PAUSETIMER_REG
  [15:0] TX_PAUSETIMER — TX Pause Timer Value
0x370 CPSW_NUSS_VBUSP_PN_MAC_TX_PAUSETIMER_REG
  [15:0] TX_PAUSETIMER — TX Pause Timer Value
0x370 CPSW_NUSS_VBUSP_PN_MAC_TX_PAUSETIMER_REG
  [15:0] TX_PAUSETIMER — TX Pause Timer Value
0x380 CPSW_NUSS_VBUSP_PN_MAC_TXN_PAUSETIMER_REG
  [15:0] TX_PAUSETIMER — TX Pause Timer Value
0x380 CPSW_NUSS_VBUSP_PN_MAC_TXN_PAUSETIMER_REG
  [15:0] TX_PAUSETIMER — TX Pause Timer Value
0x380 CPSW_NUSS_VBUSP_PN_MAC_TXN_PAUSETIMER_REG
  [15:0] TX_PAUSETIMER — TX Pause Timer Value
0x380 CPSW_NUSS_VBUSP_PN_MAC_TXN_PAUSETIMER_REG
  [15:0] TX_PAUSETIMER — TX Pause Timer Value
0x380 CPSW_NUSS_VBUSP_PN_MAC_TXN_PAUSETIMER_REG
  [15:0] TX_PAUSETIMER — TX Pause Timer Value
0x380 CPSW_NUSS_VBUSP_PN_MAC_TXN_PAUSETIMER_REG
  [15:0] TX_PAUSETIMER — TX Pause Timer Value
0x380 CPSW_NUSS_VBUSP_PN_MAC_TXN_PAUSETIMER_REG
  [15:0] TX_PAUSETIMER — TX Pause Timer Value
0x380 CPSW_NUSS_VBUSP_PN_MAC_TXN_PAUSETIMER_REG
  [15:0] TX_PAUSETIMER — TX Pause Timer Value
0x3A0 CPSW_NUSS_VBUSP_PN_MAC_EMCONTROL_REG
  [1] SOFT — Emulation Soft Bit
  [0] FREE — Emulation Free Bit
0x3A0 CPSW_NUSS_VBUSP_PN_MAC_EMCONTROL_REG
  [1] SOFT — Emulation Soft Bit
  [0] FREE — Emulation Free Bit
0x3A0 CPSW_NUSS_VBUSP_PN_MAC_EMCONTROL_REG
  [1] SOFT — Emulation Soft Bit
  [0] FREE — Emulation Free Bit
0x3A0 CPSW_NUSS_VBUSP_PN_MAC_EMCONTROL_REG
  [1] SOFT — Emulation Soft Bit
  [0] FREE — Emulation Free Bit
0x3A0 CPSW_NUSS_VBUSP_PN_MAC_EMCONTROL_REG
  [1] SOFT — Emulation Soft Bit
  [0] FREE — Emulation Free Bit
0x3A0 CPSW_NUSS_VBUSP_PN_MAC_EMCONTROL_REG
  [1] SOFT — Emulation Soft Bit
  [0] FREE — Emulation Free Bit
0x3A0 CPSW_NUSS_VBUSP_PN_MAC_EMCONTROL_REG
  [1] SOFT — Emulation Soft Bit
  [0] FREE — Emulation Free Bit
0x3A0 CPSW_NUSS_VBUSP_PN_MAC_EMCONTROL_REG
  [1] SOFT — Emulation Soft Bit
  [0] FREE — Emulation Free Bit
0x3A4 CPSW_NUSS_VBUSP_PN_MAC_TX_GAP_REG reset 0xC
  [15:0] TX_GAP — Transmit Inter-Packet Gap
0x3A4 CPSW_NUSS_VBUSP_PN_MAC_TX_GAP_REG reset 0xC
  [15:0] TX_GAP — Transmit Inter-Packet Gap
0x3A4 CPSW_NUSS_VBUSP_PN_MAC_TX_GAP_REG reset 0xC
  [15:0] TX_GAP — Transmit Inter-Packet Gap
0x3A4 CPSW_NUSS_VBUSP_PN_MAC_TX_GAP_REG reset 0xC
  [15:0] TX_GAP — Transmit Inter-Packet Gap
0x3A4 CPSW_NUSS_VBUSP_PN_MAC_TX_GAP_REG reset 0xC
  [15:0] TX_GAP — Transmit Inter-Packet Gap
0x3A4 CPSW_NUSS_VBUSP_PN_MAC_TX_GAP_REG reset 0xC
  [15:0] TX_GAP — Transmit Inter-Packet Gap
0x3A4 CPSW_NUSS_VBUSP_PN_MAC_TX_GAP_REG reset 0xC
  [15:0] TX_GAP — Transmit Inter-Packet Gap
0x3A4 CPSW_NUSS_VBUSP_PN_MAC_TX_GAP_REG reset 0xC
  [15:0] TX_GAP — Transmit Inter-Packet Gap
0x3A8 CPSW_NUSS_VBUSP_PN_MAC_PORT_CONFIG ro reset 0x310
  [9] IET — IET support
  [8] XGMII — XGMII support
  [7:0] INTERVLAN_ROUTES — The number of InterVLAN routes
0x3A8 CPSW_NUSS_VBUSP_PN_MAC_PORT_CONFIG ro reset 0x310
  fields as CPSW_NUSS_VBUSP_PN_MAC_PORT_CONFIG
0x3A8 CPSW_NUSS_VBUSP_PN_MAC_PORT_CONFIG ro reset 0x208
  fields as CPSW_NUSS_VBUSP_PN_MAC_PORT_CONFIG
0x3A8 CPSW_NUSS_VBUSP_PN_MAC_PORT_CONFIG ro reset 0x208
  fields as CPSW_NUSS_VBUSP_PN_MAC_PORT_CONFIG
0x3A8 CPSW_NUSS_VBUSP_PN_MAC_PORT_CONFIG ro reset 0x208
  fields as CPSW_NUSS_VBUSP_PN_MAC_PORT_CONFIG
0x3A8 CPSW_NUSS_VBUSP_PN_MAC_PORT_CONFIG ro reset 0x208
  fields as CPSW_NUSS_VBUSP_PN_MAC_PORT_CONFIG
0x3A8 CPSW_NUSS_VBUSP_PN_MAC_PORT_CONFIG ro reset 0x208
  fields as CPSW_NUSS_VBUSP_PN_MAC_PORT_CONFIG
0x3A8 CPSW_NUSS_VBUSP_PN_MAC_PORT_CONFIG ro reset 0x208
  fields as CPSW_NUSS_VBUSP_PN_MAC_PORT_CONFIG
0x3AC CPSW_NUSS_VBUSP_PN_INTERVLAN_OPX_POINTER_REG
  [4:0] POINTER — InterVLAN location pointer: This field points to the InterVLAN location that will be read/written by accesses to Enet_Pn_InterVLANx_A/B.
0x3AC CPSW_NUSS_VBUSP_PN_INTERVLAN_OPX_POINTER_REG
  fields as CPSW_NUSS_VBUSP_PN_INTERVLAN_OPX_POINTER_REG
0x3AC CPSW_NUSS_VBUSP_PN_INTERVLAN_OPX_POINTER_REG
  [3:0] POINTER — InterVLAN location pointer: This field points to the InterVLAN location that will be read/written by accesses to Enet_Pn_InterVLANx_A/B.
0x3AC CPSW_NUSS_VBUSP_PN_INTERVLAN_OPX_POINTER_REG
  [3:0] POINTER — InterVLAN location pointer: This field points to the InterVLAN location that will be read/written by accesses to Enet_Pn_InterVLANx_A/B.
0x3AC CPSW_NUSS_VBUSP_PN_INTERVLAN_OPX_POINTER_REG
  [3:0] POINTER — InterVLAN location pointer: This field points to the InterVLAN location that will be read/written by accesses to Enet_Pn_InterVLANx_A/B.
0x3AC CPSW_NUSS_VBUSP_PN_INTERVLAN_OPX_POINTER_REG
  [3:0] POINTER — InterVLAN location pointer: This field points to the InterVLAN location that will be read/written by accesses to Enet_Pn_InterVLANx_A/B.
0x3AC CPSW_NUSS_VBUSP_PN_INTERVLAN_OPX_POINTER_REG
  [3:0] POINTER — InterVLAN location pointer: This field points to the InterVLAN location that will be read/written by accesses to Enet_Pn_InterVLANx_A/B.
0x3AC CPSW_NUSS_VBUSP_PN_INTERVLAN_OPX_POINTER_REG
  [3:0] POINTER — InterVLAN location pointer: This field points to the InterVLAN location that will be read/written by accesses to Enet_Pn_InterVLANx_A/B.
0x3B0 CPSW_NUSS_VBUSP_PN_INTERVLAN_OPX_A_REG
  [31:24] DA_23_16 — Destination Address bits 23:16
  [23:16] DA_31_24 — Destination Address bits 31:24
  [15:8] DA_39_32 — Destination Address bits 39:32
  [7:0] DA_47_40 — Destination Address bits 47:40
0x3B0 CPSW_NUSS_VBUSP_PN_INTERVLAN_OPX_A_REG
  fields as CPSW_NUSS_VBUSP_PN_INTERVLAN_OPX_A_REG
0x3B0 CPSW_NUSS_VBUSP_PN_INTERVLAN_OPX_A_REG
  fields as CPSW_NUSS_VBUSP_PN_INTERVLAN_OPX_A_REG
0x3B0 CPSW_NUSS_VBUSP_PN_INTERVLAN_OPX_A_REG
  fields as CPSW_NUSS_VBUSP_PN_INTERVLAN_OPX_A_REG
0x3B0 CPSW_NUSS_VBUSP_PN_INTERVLAN_OPX_A_REG
  fields as CPSW_NUSS_VBUSP_PN_INTERVLAN_OPX_A_REG
0x3B0 CPSW_NUSS_VBUSP_PN_INTERVLAN_OPX_A_REG
  fields as CPSW_NUSS_VBUSP_PN_INTERVLAN_OPX_A_REG
0x3B0 CPSW_NUSS_VBUSP_PN_INTERVLAN_OPX_A_REG
  fields as CPSW_NUSS_VBUSP_PN_INTERVLAN_OPX_A_REG
0x3B0 CPSW_NUSS_VBUSP_PN_INTERVLAN_OPX_A_REG
  fields as CPSW_NUSS_VBUSP_PN_INTERVLAN_OPX_A_REG
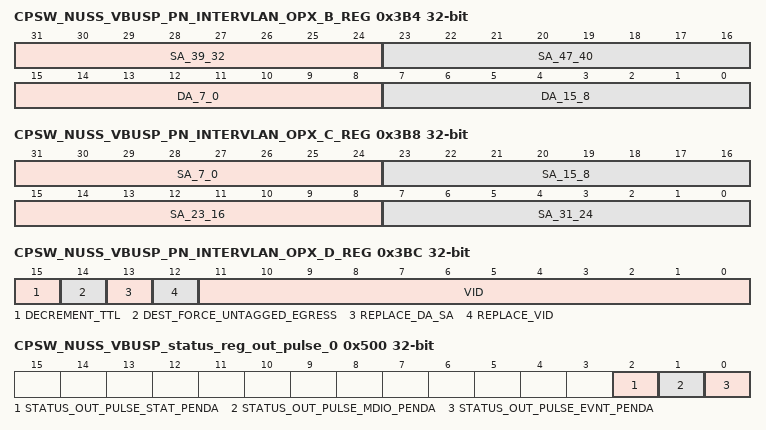
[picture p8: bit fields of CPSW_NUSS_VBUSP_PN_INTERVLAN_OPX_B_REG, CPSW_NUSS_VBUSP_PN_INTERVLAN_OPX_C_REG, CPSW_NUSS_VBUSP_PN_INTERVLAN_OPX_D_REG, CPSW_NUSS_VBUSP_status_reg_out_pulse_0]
0x3B4 CPSW_NUSS_VBUSP_PN_INTERVLAN_OPX_B_REG
  [31:24] SA_39_32 — Source Address bits 39:32
  [23:16] SA_47_40 — Source Address bits 47:40
  [15:8] DA_7_0 — Destination Address bits 7:0
  [7:0] DA_15_8 — Destination Address bits 15:8
0x3B4 CPSW_NUSS_VBUSP_PN_INTERVLAN_OPX_B_REG
  fields as CPSW_NUSS_VBUSP_PN_INTERVLAN_OPX_B_REG
0x3B4 CPSW_NUSS_VBUSP_PN_INTERVLAN_OPX_B_REG
  fields as CPSW_NUSS_VBUSP_PN_INTERVLAN_OPX_B_REG
0x3B4 CPSW_NUSS_VBUSP_PN_INTERVLAN_OPX_B_REG
  fields as CPSW_NUSS_VBUSP_PN_INTERVLAN_OPX_B_REG
0x3B4 CPSW_NUSS_VBUSP_PN_INTERVLAN_OPX_B_REG
  fields as CPSW_NUSS_VBUSP_PN_INTERVLAN_OPX_B_REG
0x3B4 CPSW_NUSS_VBUSP_PN_INTERVLAN_OPX_B_REG
  fields as CPSW_NUSS_VBUSP_PN_INTERVLAN_OPX_B_REG
0x3B4 CPSW_NUSS_VBUSP_PN_INTERVLAN_OPX_B_REG
  fields as CPSW_NUSS_VBUSP_PN_INTERVLAN_OPX_B_REG
0x3B4 CPSW_NUSS_VBUSP_PN_INTERVLAN_OPX_B_REG
  fields as CPSW_NUSS_VBUSP_PN_INTERVLAN_OPX_B_REG
0x3B8 CPSW_NUSS_VBUSP_PN_INTERVLAN_OPX_C_REG
  [31:24] SA_7_0 — Source Address bits 7:0
  [23:16] SA_15_8 — Source Address bits 15:8
  [15:8] SA_23_16 — Source Address bits 23:16
  [7:0] SA_31_24 — Source Address bits 31:24
0x3B8 CPSW_NUSS_VBUSP_PN_INTERVLAN_OPX_C_REG
  fields as CPSW_NUSS_VBUSP_PN_INTERVLAN_OPX_C_REG
0x3B8 CPSW_NUSS_VBUSP_PN_INTERVLAN_OPX_C_REG
  fields as CPSW_NUSS_VBUSP_PN_INTERVLAN_OPX_C_REG
0x3B8 CPSW_NUSS_VBUSP_PN_INTERVLAN_OPX_C_REG
  fields as CPSW_NUSS_VBUSP_PN_INTERVLAN_OPX_C_REG
0x3B8 CPSW_NUSS_VBUSP_PN_INTERVLAN_OPX_C_REG
  fields as CPSW_NUSS_VBUSP_PN_INTERVLAN_OPX_C_REG
0x3B8 CPSW_NUSS_VBUSP_PN_INTERVLAN_OPX_C_REG
  fields as CPSW_NUSS_VBUSP_PN_INTERVLAN_OPX_C_REG
0x3B8 CPSW_NUSS_VBUSP_PN_INTERVLAN_OPX_C_REG
  fields as CPSW_NUSS_VBUSP_PN_INTERVLAN_OPX_C_REG
0x3B8 CPSW_NUSS_VBUSP_PN_INTERVLAN_OPX_C_REG
  fields as CPSW_NUSS_VBUSP_PN_INTERVLAN_OPX_C_REG
0x3BC CPSW_NUSS_VBUSP_PN_INTERVLAN_OPX_D_REG
  [15] DECREMENT_TTL — Decrement Time To Live: When set, the Time To Live (TTL) field in the header is decremented.
  [14] DEST_FORCE_UNTAGGED_EGRESS — Destination VLAN Force Untagged Egress: When set, this bit indicates that the VLAN should be removed on egress for the routed packet.
  [13] REPLACE_DA_SA — Replace Destination Address and Source Address: When set this bit indicates that the routed packet destination address should be replaced by da[47:0] and the source address should be replaced by sa[47:0].
  [12] REPLACE_VID — Replace VLAN ID: When set this bit indicates that the VLAN ID should be replaced for the routed packet.
  [11:0] VID — VLAN ID
0x3BC CPSW_NUSS_VBUSP_PN_INTERVLAN_OPX_D_REG
  fields as CPSW_NUSS_VBUSP_PN_INTERVLAN_OPX_D_REG
0x3BC CPSW_NUSS_VBUSP_PN_INTERVLAN_OPX_D_REG
  fields as CPSW_NUSS_VBUSP_PN_INTERVLAN_OPX_D_REG
0x3BC CPSW_NUSS_VBUSP_PN_INTERVLAN_OPX_D_REG
  fields as CPSW_NUSS_VBUSP_PN_INTERVLAN_OPX_D_REG
0x3BC CPSW_NUSS_VBUSP_PN_INTERVLAN_OPX_D_REG
  fields as CPSW_NUSS_VBUSP_PN_INTERVLAN_OPX_D_REG
0x3BC CPSW_NUSS_VBUSP_PN_INTERVLAN_OPX_D_REG
  fields as CPSW_NUSS_VBUSP_PN_INTERVLAN_OPX_D_REG
0x3BC CPSW_NUSS_VBUSP_PN_INTERVLAN_OPX_D_REG
  fields as CPSW_NUSS_VBUSP_PN_INTERVLAN_OPX_D_REG
0x3BC CPSW_NUSS_VBUSP_PN_INTERVLAN_OPX_D_REG
  fields as CPSW_NUSS_VBUSP_PN_INTERVLAN_OPX_D_REG
0x500 CPSW_NUSS_VBUSP_status_reg_out_pulse_0 ro
  [2] STATUS_OUT_PULSE_STAT_PENDA — Status for out_pulse_en_stat_penda
  [1] STATUS_OUT_PULSE_MDIO_PENDA — Status for out_pulse_en_mdio_penda
  [0] STATUS_OUT_PULSE_EVNT_PENDA — Status for out_pulse_en_evnt_penda
0xA80 CPSW_NUSS_VBUSP_intr_vector_reg_out_pulse ro
  [31:0] INTR_VECTOR_OUT_PULSE — Interrupt Vector
